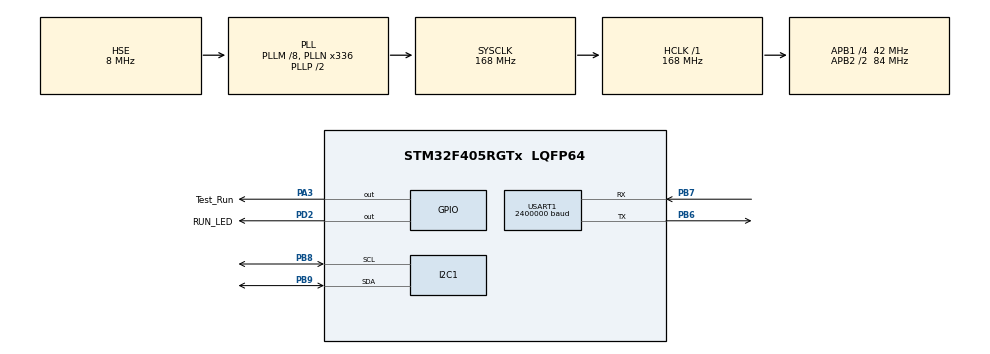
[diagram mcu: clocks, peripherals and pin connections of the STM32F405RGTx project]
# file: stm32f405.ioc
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Dma.Request0=USART1_RX
Dma.USART1_RX.0.Direction=DMA_PERIPH_TO_MEMORY
Dma.USART1_RX.0.FIFOMode=DMA_FIFOMODE_DISABLE
Dma.USART1_RX.0.Instance=DMA2_Stream2
Dma.USART1_RX.0.MemDataAlignment=DMA_MDATAALIGN_BYTE
Dma.USART1_RX.0.MemInc=DMA_MINC_ENABLE
Dma.USART1_RX.0.Mode=DMA_NORMAL
Dma.USART1_RX.0.PeriphDataAlignment=DMA_PDATAALIGN_BYTE
Dma.USART1_RX.0.PeriphInc=DMA_PINC_DISABLE
Dma.USART1_RX.0.Priority=DMA_PRIORITY_HIGH
Mcu.Family=STM32F4
Mcu.Name=STM32F405RGTx
Mcu.Package=LQFP64
NVIC.DMA2_Stream2_IRQn=true\:0\:0\:false\:false\:true\:false\:true\:true
NVIC.PriorityGroup=NVIC_PRIORITYGROUP_4
NVIC.TIM8_TRG_COM_TIM14_IRQn=true\:0\:0\:false\:false\:true\:true\:true\:true
NVIC.USART1_IRQn=true\:1\:0\:true\:false\:true\:true\:true\:true
PA13.Mode=Serial_Wire
PA13.Signal=SYS_JTMS-SWDIO
PA14.Mode=Serial_Wire
PA14.Signal=SYS_JTCK-SWCLK
PA3.GPIO_Label=Test_Run
PA3.GPIO_PuPd=GPIO_PULLDOWN
PA3.GPIO_Speed=GPIO_SPEED_FREQ_VERY_HIGH
PA3.PinState=GPIO_PIN_RESET
PA3.Signal=GPIO_Output
PB6.GPIO_Speed=GPIO_SPEED_FREQ_HIGH
PB6.Mode=Asynchronous
PB6.Signal=USART1_TX
PB7.GPIO_Speed=GPIO_SPEED_FREQ_HIGH
PB7.Mode=Asynchronous
PB7.Signal=USART1_RX
PB8.Mode=I2C
PB8.Signal=I2C1_SCL
PB9.Mode=I2C
PB9.Signal=I2C1_SDA
PD2.GPIO_Label=RUN_LED
PD2.GPIO_PuPd=GPIO_PULLDOWN
PD2.GPIO_Speed=GPIO_SPEED_FREQ_MEDIUM
PD2.PinState=GPIO_PIN_RESET
PD2.Signal=GPIO_Output
PH0-OSC_IN.Mode=HSE-External-Oscillator
PH0-OSC_IN.Signal=RCC_OSC_IN
PH1-OSC_OUT.Mode=HSE-External-Oscillator
PH1-OSC_OUT.Signal=RCC_OSC_OUT
ProjectManager.HeapSize=0x200
ProjectManager.StackSize=0x400
ProjectManager.TargetToolchain=MDK-ARM V5.32
RCC.48MHZClocksFreq_Value=84000000
RCC.AHBFreq_Value=168000000
RCC.APB1CLKDivider=RCC_HCLK_DIV4
RCC.APB1Freq_Value=42000000
RCC.APB1TimFreq_Value=84000000
RCC.APB2CLKDivider=RCC_HCLK_DIV2
RCC.APB2Freq_Value=84000000
RCC.APB2TimFreq_Value=168000000
RCC.CortexFreq_Value=168000000
RCC.HCLKFreq_Value=168000000
RCC.HSE_VALUE=8000000
RCC.HSI_VALUE=16000000
RCC.LSE_VALUE=32768
RCC.PLLM=8
RCC.PLLN=336
RCC.PLLSourceVirtual=RCC_PLLSOURCE_HSE
RCC.SYSCLKFreq_VALUE=168000000
RCC.SYSCLKSource=RCC_SYSCLKSOURCE_PLLCLK
RCC.VCOOutputFreq_Value=336000000
TIM14.AutoReloadPreload=TIM_AUTORELOAD_PRELOAD_ENABLE
TIM14.Period=10000-1
TIM14.Prescaler=84-1
USART1.BaudRate=2400000
USART1.VirtualMode=VM_ASYNC
VP_TIM14_VS_ClockSourceINT.Mode=Enable_Timer
board=custom

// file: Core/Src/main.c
/* USER CODE BEGIN Header */
/**
  ******************************************************************************
  * @file           : main.c
  * @brief          : Main program body
  ******************************************************************************
  * @attention
  *
  * Copyright (c) 2024 STMicroelectronics.
  * All rights reserved.
  *
  * This software is licensed under terms that can be found in the LICENSE file
  * in the root directory of this software component.
  * If no LICENSE file comes with this software, it is provided AS-IS.
  *
  ******************************************************************************
  */
/* USER CODE END Header */
#include "main.h"
#include "dma.h"
#include "i2c.h"
#include "tim.h"
#include "usart.h"
#include "gpio.h"

/* USER CODE BEGIN PTD */
volatile uint8_t RTT_BufferUp0[1024] = {0,};
/* USER CODE END PTD */

void SystemClock_Config(void);

int main(void)
{

  /* MCU Configuration--------------------------------------------------------*/

  /* Reset of all peripherals, Initializes the Flash interface and the Systick. */
  HAL_Init();

  /* Configure the system clock */
  SystemClock_Config();

  /* Initialize all configured peripherals */
  MX_GPIO_Init();
  MX_DMA_Init();
  MX_USART1_UART_Init();
  MX_I2C1_Init();
  MX_TIM14_Init();
  /* USER CODE BEGIN 2 */
  // 配置MCU -> PC缓冲区（上行缓存区）
  SEGGER_RTT_ConfigUpBuffer(0,                              // 通道0
                            "Buffer0Up",                    // 通道名字
                            (uint8_t*)&RTT_BufferUp0[0],    // 缓存地址
                            sizeof(RTT_BufferUp0),          // 缓存大小
                            SEGGER_RTT_MODE_NO_BLOCK_SKIP); // 非阻塞
  /* USER CODE END 2 */

  /* Infinite loop */
  while (1)
  {

    /* USER CODE BEGIN 3 */
    HAL_GPIO_TogglePin(RUN_LED_GPIO_Port,RUN_LED_Pin);

    // 终端号0打印
    SEGGER_RTT_SetTerminal(0);                           // 设置终端0
    SEGGER_RTT_printf(0, "SysTick:%d\n", HAL_GetTick()); // 往通道0写入消息
    HAL_Delay(100);
  }
  /* USER CODE END 3 */
}

void SystemClock_Config(void)
{
  RCC_OscInitTypeDef RCC_OscInitStruct = {0};
  RCC_ClkInitTypeDef RCC_ClkInitStruct = {0};

  /** Configure the main internal regulator output voltage
  */
  __HAL_RCC_PWR_CLK_ENABLE();
  __HAL_PWR_VOLTAGESCALING_CONFIG(PWR_REGULATOR_VOLTAGE_SCALE1);

  /** Initializes the RCC Oscillators according to the specified parameters
  * in the RCC_OscInitTypeDef structure.
  */
  RCC_OscInitStruct.OscillatorType = RCC_OSCILLATORTYPE_HSE;
  RCC_OscInitStruct.HSEState = RCC_HSE_ON;
  RCC_OscInitStruct.PLL.PLLState = RCC_PLL_ON;
  RCC_OscInitStruct.PLL.PLLSource = RCC_PLLSOURCE_HSE;
  RCC_OscInitStruct.PLL.PLLM = 8;
  RCC_OscInitStruct.PLL.PLLN = 336;
  RCC_OscInitStruct.PLL.PLLP = RCC_PLLP_DIV2;
  RCC_OscInitStruct.PLL.PLLQ = 4;
  if (HAL_RCC_OscConfig(&RCC_OscInitStruct) != HAL_OK)
  {
    Error_Handler();
  }

  /** Initializes the CPU, AHB and APB buses clocks
  */
  RCC_ClkInitStruct.ClockType = RCC_CLOCKTYPE_HCLK|RCC_CLOCKTYPE_SYSCLK
                              |RCC_CLOCKTYPE_PCLK1|RCC_CLOCKTYPE_PCLK2;
  RCC_ClkInitStruct.SYSCLKSource = RCC_SYSCLKSOURCE_PLLCLK;
  RCC_ClkInitStruct.AHBCLKDivider = RCC_SYSCLK_DIV1;
  RCC_ClkInitStruct.APB1CLKDivider = RCC_HCLK_DIV4;
  RCC_ClkInitStruct.APB2CLKDivider = RCC_HCLK_DIV2;

  if (HAL_RCC_ClockConfig(&RCC_ClkInitStruct, FLASH_LATENCY_5) != HAL_OK)
  {
    Error_Handler();
  }
}

/* USER CODE BEGIN 4 */
void HAL_TIM_PeriodElapsedCallback(TIM_HandleTypeDef *htim)
{
    if (htim == (&htim14))
    {
        // 添加定时器14的中断执行
    }
}
/* USER CODE END 4 */

void Error_Handler(void)
{
  __disable_irq();
  while (1)
  {
  }
}
